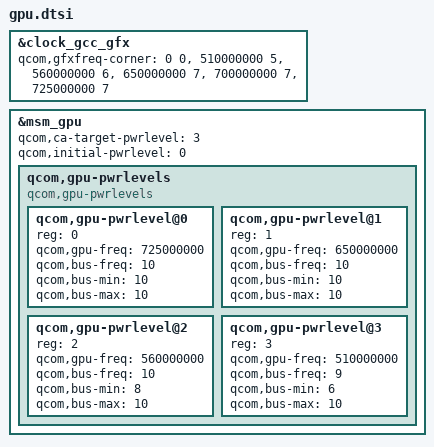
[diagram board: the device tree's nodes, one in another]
/*
 * Copyright (c) 2015-2017, The Linux Foundation. All rights reserved.
 *
 * This program is free software; you can redistribute it and/or modify
 * it under the terms of the GNU General Public License version 2 and
 * only version 2 as published by the Free Software Foundation.
 *
 * This program is distributed in the hope that it will be useful,
 * but WITHOUT ANY WARRANTY; without even the implied warranty of
 * MERCHANTABILITY or FITNESS FOR A PARTICULAR PURPOSE.  See the
 * GNU General Public License for more details.
 */

&clock_gcc_gfx {
	qcom,gfxfreq-corner =
		 <         0   0 >,
		 < 510000000   5 >,  /* NOM       */
		 < 560000000   6 >,  /* Nom Plus  */
		 < 650000000   7 >,  /* Turbo     */
		 < 700000000   7 >,  /* Turbo     */
		 < 725000000   7 >;  /* Turbo     */
};

&msm_gpu {

	qcom,ca-target-pwrlevel = <3>;
	qcom,initial-pwrlevel = <0>;
	/delete-node/qcom,gpu-pwrlevels;

	/* Power levels */
	qcom,gpu-pwrlevels {
		#address-cells = <1>;
		#size-cells = <0>;

		compatible = "qcom,gpu-pwrlevels";
		/* TURBO LD0 */
		qcom,gpu-pwrlevel@0 {
			reg = <0>;
			qcom,gpu-freq = <725000000>;
			qcom,bus-freq = <10>;
			qcom,bus-min = <10>;
			qcom,bus-max = <10>;
		};

		/* TURBO */
		qcom,gpu-pwrlevel@1 {
			reg = <1>;
			qcom,gpu-freq = <650000000>;
			qcom,bus-freq = <10>;
			qcom,bus-min = <10>;
			qcom,bus-max = <10>;
		};

		/* NOM+ */
		qcom,gpu-pwrlevel@2 {
			reg = <2>;
			qcom,gpu-freq = <560000000>;
			qcom,bus-freq = <10>;
			qcom,bus-min = <8>;
			qcom,bus-max = <10>;
		};

		/* NOM */
		qcom,gpu-pwrlevel@3 {
			reg = <3>;
			qcom,gpu-freq = <510000000>;
			qcom,bus-freq = <9>;
			qcom,bus-min = <6>;
			qcom,bus-max = <10>;
		};
	};
};
